AUTOSAR XML (schema 4.0)
package /S09SDK/If
  sender receiver interface InfoLink
    data val
  sender receiver interface BodyCmd
    data val
  sender receiver interface TelemetryLink
    data val
package /S09SDK/Swc
  application sw component type HeadUnit
    provide port ivitogwOut: provided-interface=InfoLink
  application sw component type ThirdPartyAdSdk
    provide port sdktogwOut: provided-interface=TelemetryLink
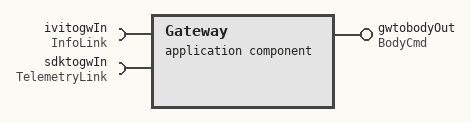
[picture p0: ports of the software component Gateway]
  application sw component type Gateway
    provide port gwtobodyOut: provided-interface=BodyCmd
    require port ivitogwIn: required-interface=InfoLink
    require port sdktogwIn: required-interface=TelemetryLink
  application sw component type BodyCtrl
    require port gwtobodyIn: required-interface=BodyCmd
  composition sw component type Root
    4 x component:
      ivi: type=HeadUnit
      sdk: type=ThirdPartyAdSdk
      gw: type=Gateway
      body: type=BodyCtrl
    connect ivi.ivitogwOut -> gw.ivitogwIn
    connect gw.gwtobodyOut -> body.gwtobodyIn
    connect sdk.sdktogwOut -> gw.sdktogwIn
package /S09SDK/Comm
  pdu ivitogwIPdu
    signal ivitogwISig: system signal ivitogwSSig
  secured i pdu ivitogwSecuredIPdu: auth-info-tx-length=32, freshness-value-id=1, freshness-value-length=8, payload=ivitogwIPdu
  pdu gwtobodyIPdu
    signal gwtobodyISig: system signal gwtobodySSig
  secured i pdu gwtobodySecuredIPdu: auth-info-tx-length=32, freshness-value-id=1, freshness-value-length=8, payload=gwtobodyIPdu
  pdu sdktogwIPdu
    signal sdktogwISig: system signal sdktogwSSig
package /S09SDK/Topology
  ecu instance BodyEcu
  ecu instance GatewayEcu
  ecu instance TelematicsEcu
  system Veh
    root-software-compositions:
      root sw composition prototype Root: software-composition=Root
    system mapping Map
      data-mappings:
        data-element=Root.ivitogwOut.val, system-signal=ivitogwSSig
        data-element=Root.gwtobodyOut.val, system-signal=gwtobodySSig
        data-element=Root.sdktogwOut.val, system-signal=sdktogwSSig
      sw-mappings:
        swc to ecu mapping ToBodyEcu: component=body, ecu-instance=BodyEcu
        swc to ecu mapping ToGatewayEcu: component=gw, ecu-instance=GatewayEcu
        swc to ecu mapping ToTelematicsEcu: component=[ivi, sdk], ecu-instance=TelematicsEcu
